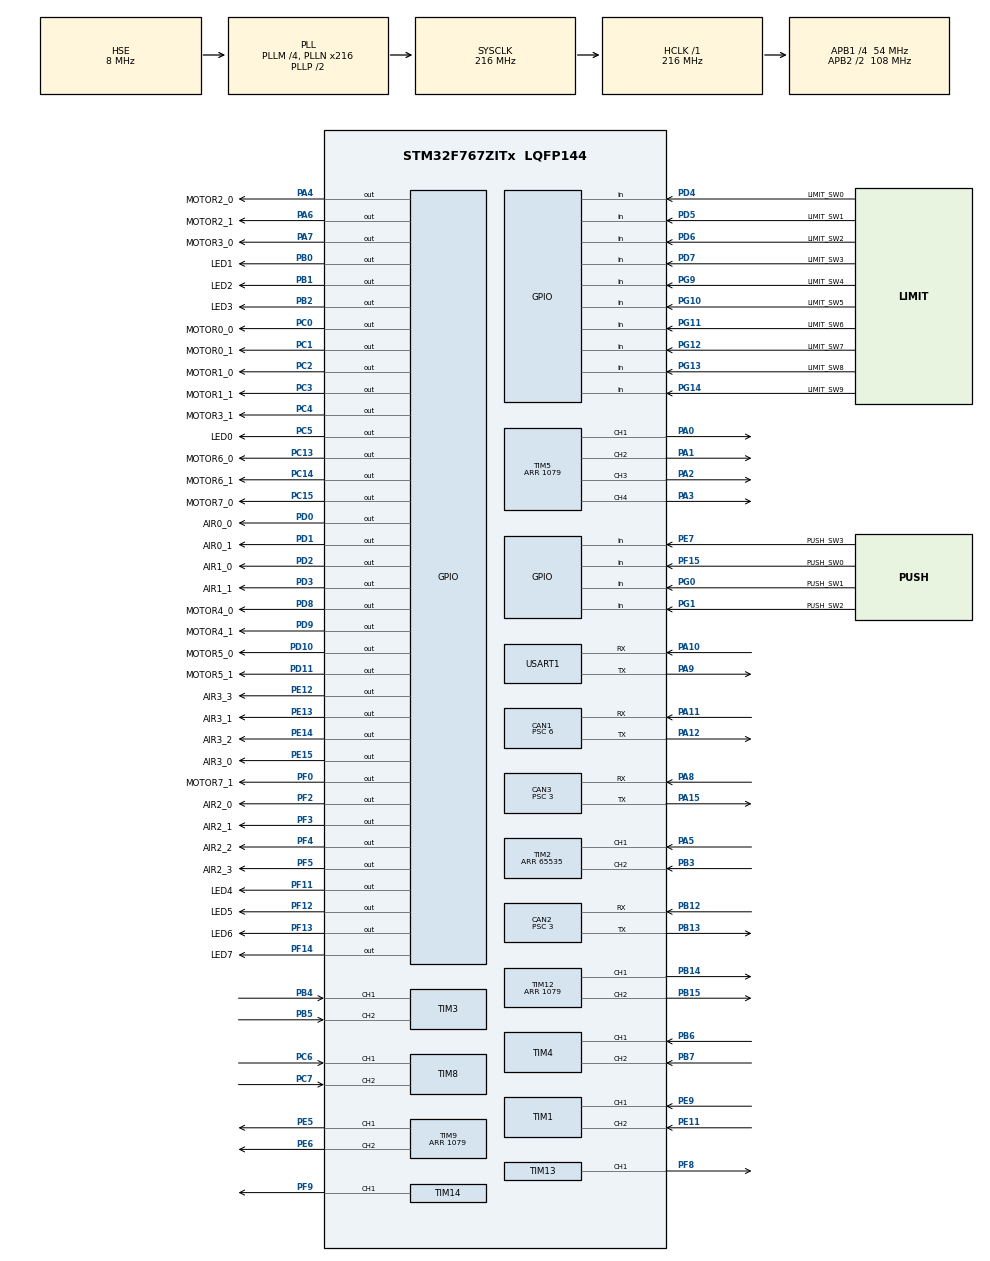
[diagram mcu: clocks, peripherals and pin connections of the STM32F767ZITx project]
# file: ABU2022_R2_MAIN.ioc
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CAN1.BS1=CAN_BS1_14TQ
CAN1.BS2=CAN_BS2_3TQ
CAN1.CalculateBaudRate=500000
CAN1.CalculateTimeBit=1999.99
CAN1.CalculateTimeQuantum=111.11111111111111
CAN1.Prescaler=6
CAN2.BS1=CAN_BS1_14TQ
CAN2.BS2=CAN_BS2_3TQ
CAN2.CalculateBaudRate=1000000
CAN2.CalculateTimeBit=999.99
CAN2.CalculateTimeQuantum=55.55555555555556
CAN2.Prescaler=3
CAN3.BS1=CAN_BS1_14TQ
CAN3.BS2=CAN_BS2_3TQ
CAN3.CalculateBaudRate=1000000
CAN3.CalculateTimeBit=999.99
CAN3.CalculateTimeQuantum=55.55555555555556
CAN3.Prescaler=3
Mcu.Family=STM32F7
Mcu.Name=STM32F767ZITx
Mcu.Package=LQFP144
NVIC.CAN3_RX0_IRQn=true\:0\:0\:false\:false\:true\:true\:true
NVIC.CAN3_RX1_IRQn=true\:0\:0\:false\:false\:true\:true\:true
NVIC.CAN3_SCE_IRQn=true\:0\:0\:false\:false\:true\:true\:true
NVIC.CAN3_TX_IRQn=true\:0\:0\:false\:false\:true\:true\:true
NVIC.PriorityGroup=NVIC_PRIORITYGROUP_4
NVIC.TIM6_DAC_IRQn=true\:0\:0\:false\:false\:true\:true\:true
NVIC.TIM7_IRQn=true\:0\:0\:false\:false\:true\:true\:true
PA0/WKUP.Signal=S_TIM5_CH1
PA1.Signal=S_TIM5_CH2
PA10.Mode=Asynchronous
PA10.Signal=USART1_RX
PA11.Mode=CAN_Activate
PA11.Signal=CAN1_RX
PA12.Mode=CAN_Activate
PA12.Signal=CAN1_TX
PA13.Mode=Serial_Wire
PA13.Signal=SYS_JTMS-SWDIO
PA14.Mode=Serial_Wire
PA14.Signal=SYS_JTCK-SWCLK
PA15.Mode=CAN_Activate
PA15.Signal=CAN3_TX
PA2.Signal=S_TIM5_CH3
PA3.Signal=S_TIM5_CH4
PA4.GPIO_Label=MOTOR2_0
PA4.Signal=GPIO_Output
PA5.Signal=S_TIM2_CH1_ETR
PA6.GPIO_Label=MOTOR2_1
PA6.Signal=GPIO_Output
PA7.GPIO_Label=MOTOR3_0
PA7.Signal=GPIO_Output
PA8.Mode=CAN_Activate
PA8.Signal=CAN3_RX
PA9.Mode=Asynchronous
PA9.Signal=USART1_TX
PB0.GPIO_Label=LED1
PB0.Signal=GPIO_Output
PB1.GPIO_Label=LED2
PB1.Signal=GPIO_Output
PB12.Mode=CAN_Activate
PB12.Signal=CAN2_RX
PB13.Mode=CAN_Activate
PB13.Signal=CAN2_TX
PB14.Signal=S_TIM12_CH1
PB15.Signal=S_TIM12_CH2
PB2.GPIO_Label=LED3
PB2.Signal=GPIO_Output
PB3.Signal=S_TIM2_CH2
PB4.Signal=S_TIM3_CH1
PB5.Signal=S_TIM3_CH2
PB6.Signal=S_TIM4_CH1
PB7.Signal=S_TIM4_CH2
PC0.GPIO_Label=MOTOR0_0
PC0.Signal=GPIO_Output
PC1.GPIO_Label=MOTOR0_1
PC1.Signal=GPIO_Output
PC13.GPIO_Label=MOTOR6_0
PC13.Signal=GPIO_Output
PC14/OSC32_IN.GPIO_Label=MOTOR6_1
PC14/OSC32_IN.Signal=GPIO_Output
PC15/OSC32_OUT.GPIO_Label=MOTOR7_0
PC15/OSC32_OUT.Signal=GPIO_Output
PC2.GPIO_Label=MOTOR1_0
PC2.Signal=GPIO_Output
PC3.GPIO_Label=MOTOR1_1
PC3.Signal=GPIO_Output
PC4.GPIO_Label=MOTOR3_1
PC4.Signal=GPIO_Output
PC5.GPIO_Label=LED0
PC5.Signal=GPIO_Output
PC6.Signal=S_TIM8_CH1
PC7.Signal=S_TIM8_CH2
PD0.GPIO_Label=AIR0_0
PD0.Signal=GPIO_Output
PD1.GPIO_Label=AIR0_1
PD1.Signal=GPIO_Output
PD10.GPIO_Label=MOTOR5_0
PD10.Signal=GPIO_Output
PD11.GPIO_Label=MOTOR5_1
PD11.Signal=GPIO_Output
PD2.GPIO_Label=AIR1_0
PD2.Signal=GPIO_Output
PD3.GPIO_Label=AIR1_1
PD3.Signal=GPIO_Output
PD4.GPIO_Label=LIMIT_SW0
PD4.Signal=GPIO_Input
PD5.GPIO_Label=LIMIT_SW1
PD5.Signal=GPIO_Input
PD6.GPIO_Label=LIMIT_SW2
PD6.Signal=GPIO_Input
PD7.GPIO_Label=LIMIT_SW3
PD7.Signal=GPIO_Input
PD8.GPIO_Label=MOTOR4_0
PD8.Signal=GPIO_Output
PD9.GPIO_Label=MOTOR4_1
PD9.Signal=GPIO_Output
PE11.Signal=S_TIM1_CH2
PE12.GPIO_Label=AIR3_3
PE12.Signal=GPIO_Output
PE13.GPIO_Label=AIR3_1
PE13.Signal=GPIO_Output
PE14.GPIO_Label=AIR3_2
PE14.Signal=GPIO_Output
PE15.GPIO_Label=AIR3_0
PE15.Signal=GPIO_Output
PE5.Signal=S_TIM9_CH1
PE6.Signal=S_TIM9_CH2
PE7.GPIO_Label=PUSH_SW3
PE7.Signal=GPIO_Input
PE9.Signal=S_TIM1_CH1
PF0.GPIO_Label=MOTOR7_1
PF0.Signal=GPIO_Output
PF11.GPIO_Label=LED4
PF11.Signal=GPIO_Output
PF12.GPIO_Label=LED5
PF12.Signal=GPIO_Output
PF13.GPIO_Label=LED6
PF13.Signal=GPIO_Output
PF14.GPIO_Label=LED7
PF14.Signal=GPIO_Output
PF15.GPIO_Label=PUSH_SW0
PF15.Signal=GPIO_Input
PF2.GPIO_Label=AIR2_0
PF2.Signal=GPIO_Output
PF3.GPIO_Label=AIR2_1
PF3.Signal=GPIO_Output
PF4.GPIO_Label=AIR2_2
PF4.Signal=GPIO_Output
PF5.GPIO_Label=AIR2_3
PF5.Signal=GPIO_Output
PF8.Signal=S_TIM13_CH1
PF9.Signal=S_TIM14_CH1
PG0.GPIO_Label=PUSH_SW1
PG0.Signal=GPIO_Input
PG1.GPIO_Label=PUSH_SW2
PG1.Signal=GPIO_Input
PG10.GPIO_Label=LIMIT_SW5
PG10.Signal=GPIO_Input
PG11.GPIO_Label=LIMIT_SW6
PG11.Signal=GPIO_Input
PG12.GPIO_Label=LIMIT_SW7
PG12.Signal=GPIO_Input
PG13.GPIO_Label=LIMIT_SW8
PG13.Signal=GPIO_Input
PG14.GPIO_Label=LIMIT_SW9
PG14.Signal=GPIO_Input
PG9.GPIO_Label=LIMIT_SW4
PG9.Signal=GPIO_Input
PH0/OSC_IN.Mode=HSE-External-Oscillator
PH0/OSC_IN.Signal=RCC_OSC_IN
PH1/OSC_OUT.Mode=HSE-External-Oscillator
PH1/OSC_OUT.Signal=RCC_OSC_OUT
ProjectManager.HeapSize=0x200
ProjectManager.StackSize=0x400
ProjectManager.TargetToolchain=SW4STM32
RCC.AHBFreq_Value=216000000
RCC.APB1CLKDivider=RCC_HCLK_DIV4
RCC.APB1Freq_Value=54000000
RCC.APB1TimFreq_Value=108000000
RCC.APB2CLKDivider=RCC_HCLK_DIV2
RCC.APB2Freq_Value=108000000
RCC.APB2TimFreq_Value=216000000
RCC.CortexFreq_Value=216000000
RCC.HCLKFreq_Value=216000000
RCC.HSE_VALUE=8000000
RCC.HSI_VALUE=16000000
RCC.LSE_VALUE=32768
RCC.PLLM=4
RCC.PLLN=216
RCC.PLLSourceVirtual=RCC_PLLSOURCE_HSE
RCC.SYSCLKFreq_VALUE=216000000
RCC.SYSCLKSource=RCC_SYSCLKSOURCE_PLLCLK
RCC.USBFreq_Value=216000000
RCC.VCOOutputFreq_Value=432000000
SH.S_TIM12_CH1.0=TIM12_CH1,PWM Generation1 CH1
SH.S_TIM12_CH2.0=TIM12_CH2,PWM Generation2 CH2
SH.S_TIM13_CH1.0=TIM13_CH1,PWM Generation1 CH1
SH.S_TIM14_CH1.0=TIM14_CH1,PWM Generation1 CH1
SH.S_TIM1_CH1.0=TIM1_CH1,Encoder_Interface
SH.S_TIM1_CH2.0=TIM1_CH2,Encoder_Interface
SH.S_TIM2_CH1_ETR.0=TIM2_CH1,Encoder_Interface
SH.S_TIM2_CH2.0=TIM2_CH2,Encoder_Interface
SH.S_TIM3_CH1.0=TIM3_CH1,Encoder_Interface
SH.S_TIM3_CH2.0=TIM3_CH2,Encoder_Interface
SH.S_TIM4_CH1.0=TIM4_CH1,Encoder_Interface
SH.S_TIM4_CH2.0=TIM4_CH2,Encoder_Interface
SH.S_TIM5_CH1.0=TIM5_CH1,PWM Generation1 CH1
SH.S_TIM5_CH2.0=TIM5_CH2,PWM Generation2 CH2
SH.S_TIM5_CH3.0=TIM5_CH3,PWM Generation3 CH3
SH.S_TIM5_CH4.0=TIM5_CH4,PWM Generation4 CH4
SH.S_TIM8_CH1.0=TIM8_CH1,Encoder_Interface
SH.S_TIM8_CH2.0=TIM8_CH2,Encoder_Interface
SH.S_TIM9_CH1.0=TIM9_CH1,PWM Generation1 CH1
SH.S_TIM9_CH2.0=TIM9_CH2,PWM Generation2 CH2
TIM12.Channel-PWM\ Generation1\ CH1=TIM_CHANNEL_1
TIM12.Channel-PWM\ Generation2\ CH2=TIM_CHANNEL_2
TIM12.Period=1079
TIM13.Channel=TIM_CHANNEL_1
TIM13.Period=9999
TIM13.Prescaler=150
TIM14.Channel=TIM_CHANNEL_1
TIM14.Period=9999
TIM14.Prescaler=150
TIM2.Period=65535
TIM5.Channel-PWM\ Generation1\ CH1=TIM_CHANNEL_1
TIM5.Channel-PWM\ Generation2\ CH2=TIM_CHANNEL_2
TIM5.Channel-PWM\ Generation3\ CH3=TIM_CHANNEL_3
TIM5.Channel-PWM\ Generation4\ CH4=TIM_CHANNEL_4
TIM5.Period=1079
TIM6.Period=9999
TIM6.Prescaler=269
TIM7.Period=9999
TIM7.Prescaler=539
TIM9.Channel-PWM\ Generation1\ CH1=TIM_CHANNEL_1
TIM9.Channel-PWM\ Generation2\ CH2=TIM_CHANNEL_2
TIM9.Period=1079
USART1.VirtualMode-Asynchronous=VM_ASYNC
VP_TIM13_VS_ClockSourceINT.Mode=Enable_Timer
VP_TIM14_VS_ClockSourceINT.Mode=Enable_Timer
VP_TIM6_VS_ClockSourceINT.Mode=Enable_Timer
VP_TIM7_VS_ClockSourceINT.Mode=Enable_Timer
board=custom

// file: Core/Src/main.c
/* USER CODE BEGIN Header */
/**
  ******************************************************************************
  * @file           : main.c
  * @brief          : Main program body
  ******************************************************************************
  * @attention
  *
  * <h2><center>&copy; Copyright (c) 2022 STMicroelectronics.
  * All rights reserved.</center></h2>
  *
  * This software component is licensed by ST under BSD 3-Clause license,
  * the "License"; You may not use this file except in compliance with the
  * License. You may obtain a copy of the License at:
  *                        opensource.org/licenses/BSD-3-Clause
  *
  ******************************************************************************
  */
/* USER CODE END Header */
#include "main.h"
#include "can.h"
#include "tim.h"
#include "usart.h"
#include "gpio.h"

/* USER CODE BEGIN Includes */
#include "can_com.h"
#include "control.h"
#include "control_main.h"
#include "controller.h"
#include "encoder.h"
#include "motor.h"
#include "servo.h"
/* USER CODE END Includes */

void SystemClock_Config(void);
/* USER CODE BEGIN PFP */
void initialize();
/* USER CODE END PFP */

/* USER CODE BEGIN 0 */
uint8_t pid_stats = 0;
uint8_t disc_number = 0;
uint8_t pile_state = 0;
/* USER CODE END 0 */

int main(void)
{

  /* MCU Configuration--------------------------------------------------------*/

  /* Reset of all peripherals, Initializes the Flash interface and the Systick. */
  HAL_Init();

  /* Configure the system clock */
  SystemClock_Config();

  /* Initialize all configured peripherals */
  MX_GPIO_Init();
  MX_CAN1_Init();
  MX_TIM6_Init();
  MX_USART1_UART_Init();
  MX_TIM1_Init();
  MX_TIM2_Init();
  MX_TIM3_Init();
  MX_TIM5_Init();
  MX_TIM8_Init();
  MX_CAN2_Init();
  MX_TIM4_Init();
  MX_TIM9_Init();
  MX_TIM12_Init();
  MX_CAN3_Init();
  MX_TIM13_Init();
  MX_TIM14_Init();
  MX_TIM7_Init();
  /* USER CODE BEGIN 2 */
  initialize();
  /* USER CODE END 2 */

  /* Infinite loop */
  /* USER CODE BEGIN WHILE */
  while (1)
  {
//	  print("lagori_mode = %d:disc_num = %d\r\n",lagori_mode,get_raspi1().disc);
	  switch (lagori_mode)
	  {
	  case lagori_init:
		  if(GetController().bits.Maru)
		  {
			  LED0_OFF;
			  LED1_OFF;
			  LED2_OFF;
			  LED3_OFF;
			  lagori_mode = lagori_reset;
		  }
		  break;

	  case lagori_reset:
		  while(LIMIT_SW6_OFF)
		  {
			  Motor_6(40);
		  }

		  if(LIMIT_SW6_ON)
		  {
			  Motor_6(0);
		  }

		  while(LIMIT_SW4_OFF)
		  {
			  Motor_5(-15);
		  }

		  if(LIMIT_SW4_ON)
		  {
			  Motor_5(0);
		  }

		  if(LIMIT_SW0_OFF)
		  {
			  Motor_0(-35);
		  }
		  else if(LIMIT_SW0_ON)
		  {
			  LED0_ON;
			  Motor_0(0);
		  }

		  if(LIMIT_SW1_OFF)
		  {
			  Motor_1(-17);
		  }
		  else if(LIMIT_SW1_ON)
		  {
			  LED1_ON;
			  Motor_1(0);
		  }

		  if(LIMIT_SW2_OFF)
		  {
			  Motor_2(-30);
		  }
		  else if(LIMIT_SW2_ON)
		  {
			  LED2_ON;
			  Motor_2(0);
		  }

		  if(LIMIT_SW3_OFF)
		  {
			  Motor_3(-17);
		  }
		  else if(LIMIT_SW3_ON)
		  {
			  LED3_ON;
			  Motor_3(0);
		  }

		  if(LIMIT_SW0_ON && LIMIT_SW1_ON && LIMIT_SW2_ON && LIMIT_SW3_ON)
		  {
			  LED0_ON;
			  LED1_ON;
			  LED2_ON;
			  LED3_ON;
			  Motor_0(0);
			  Motor_1(0);
			  Motor_2(0);
			  Motor_3(0);
			  Motor_6(0);

			  HAL_Delay(200);

			  set_lift_r(0.01);
			  set_lift_l(0);
			  set_arm_right(0);
			  set_arm_left(0);
			  set_partition(0.0);

			  set_target_arm_right(0);
			  set_target_arm_left(0);
			  set_target_lift_right(0);
			  set_target_lift_left(0);
			  set_target_partition(0.0);
			  pid_stats = 1;

			  HAL_Delay(200);

			  lagori_mode = lagori_arm_mode;
		  }
		  break;

	  case lagori_arm_mode:
		  if(GetController().bits.Maru)
		  {
			  set_target_arm_right(get_arm_right_value());
			  set_target_arm_left(get_arm_left_value());
			  pid_stats = 1;
			  if(camera_state == camera_on1)
			  {
				  if(pile_mode == mode1)
				  {
					  disc_number = get_raspi1().disc_camera1;
				  }
				  else if(pile_mode == mode2)
				  {
					  disc_number = get_raspi1().disc_camera2;
				  }

				  if(disc_number >= 1 && disc_number <= 5)
				  {
					  if(get_raspi1().state)
					  {
						  while(arm_ready(0.0) == 0)
						  {
							  LED1_TOGGLE;
						  }
						  lagori_mode = lagori_disc_fix;
					  }
					  else
					  {
						  lagori_mode = lagori_arm_on;
					  }
				  }
			  }
			  else if(camera_state == camera_on2)
			  {
				  if((get_raspi1().disc_camera1 >= 1) && (get_raspi1().disc_camera1 <= 5))
				  {
					  disc_number = get_raspi1().disc_camera1;
				  }
				  else if((get_disc_count() >= 1) && (get_disc_count() <= 5))
				  {
					  disc_number = get_disc_count();
				  }

				  if(disc_number >= 1 && disc_number <= 5)
				  {
					  lagori_mode = lagori_arm_on;
				  }
			  }
		  }
		  else if(GetController().bits.Sankaku)
		  {
			  lagori_mode = lagori_pile;
		  }
		  else if(GetController().bits.Shikaku)
		  {
			  disc_count();
		  }
		  else if(GetController().bits.Batu)
		  {
			  pid_stats = 0;
			  arm_mode_change();
		  }
		  else if(GetController().bits.Start)
		  {
			  camera_state_change();
		  }
		  break;

	  case lagori_disc_fix:
		  switch(disc_number)
		  {
		  case 1:
			  while(lift_right_ready(0.167) == 0)
			  {
				  LED0_TOGGLE;
			  }
			  break;

		  case 2:
			  while(lift_right_ready(0.18) == 0)
			  {
				  LED0_TOGGLE;
			  }

			  break;

		  case 3:
			  while(lift_right_ready(0.26) == 0)
			  {
				  LED0_TOGGLE;
			  }

			  break;

		  case 4:
			  while(lift_right_ready(0.28) == 0)
			  {
				  LED0_TOGGLE;
			  }

			  break;

		  case 5:
			  while(lift_right_ready(0.38) == 0)
			  {
				  LED0_TOGGLE;
			  }

			  break;
		  }

		  while(arm_right_ready(0.4) == 0)
		  {
			  LED1_TOGGLE;
			  Motor_7(50);
		  }

		  if(disc_number == 1)
		  {
			  while(lift_right_ready(0.24) == 0)
			  {
				  LED0_TOGGLE;
			  }
		  }

		  while(arm_right_ready(0.0) == 0)
		  {
			  LED1_TOGGLE;
		  }
		  HAL_Delay(1200);

		  while(lift_right_ready(0.0) == 0)
		  {
			  LED0_TOGGLE;
		  }

		  reset_value();
		  lagori_mode = lagori_arm_mode;

		  break;

	  case lagori_arm_on:
		  switch(disc_number)
		  {
		  case 1:
			  arm_right_ready(0.29);

			  while(arm_left_ready(0.32) == 0)
			  {
				  LED1_TOGGLE;
			  }
			  arm_left_ready(0.35);

			  break;

		  case 2:
			  arm_left_ready(0.12);

			  while(arm_right_ready(0.365) == 0)
			  {
				  LED1_TOGGLE;
			  }
			  arm_right_ready(0.4);

			  break;

		  case 3:
			  arm_left_ready(0.145);

			  while(arm_right_ready(0.270) == 0)
			  {
				  LED1_TOGGLE;
			  }
			  arm_right_ready(0.31);
			  break;

		  case 4:
			  arm_left_ready(0.09);

			  while(arm_right_ready(0.17) == 0)
			  {
				  LED1_TOGGLE;
			  }
			  arm_right_ready(0.24);
			  break;

		  case 5:
			  arm_left_ready(0.1);

			  while(arm_right_ready(0.11) == 0)
			  {
				  LED1_TOGGLE;
			  }
			  arm_right_ready(0.15);

			  break;
		  }

		  HAL_Delay(100);
		  lagori_mode = lagori_lift_up;

		  break;

	  case lagori_lift_up:
		  switch(disc_number)
		  {
		  case 1:
			  lift_up_1();

			  break;

		  case 2:
			  lift_up_2();
			  break;

		  case 3:
			  lift_up_3();
			  break;

		  case 4:
			  if(camera_state == camera_on1)
			  {
				  while(!lift_ready(HIGHT4_CAMERA))
				  {
					  LED0_TOGGLE;
				  }
				  partition_mode = part_on;
				  partition_air = air_down_on;
			  }
			  else
			  {
				  while(!lift_ready(HIGHT4))
				  {
					  LED0_TOGGLE;
				  }
			  }
			  break;

		  case 5:
			  if(camera_state == camera_on1)
			  {
				  while(!lift_ready(HIGHT5))
				  {
					  LED0_TOGGLE;
				  }
				  partition_mode = part_off;
			  }
			  else
			  {
				  while(!lift_ready(HIGHT5))
				  {
					  LED0_TOGGLE;
				  }
			  }
			  break;
		  }

		  if(camera_state == camera_on1)
		  {
			  if(partition_air == air_up_on)
			  {
				  AIR2_0_OFF;
			  }
			  else if(partition_air == air_down_on)
			  {
				  AIR2_1_OFF;
			  }

			  if(partition_mode == part_on)
			  {
				  lagori_mode = partition_on;
			  }
			  else
			  {
				  while(1)
				  {
					  if(GetController().bits.Maru)
					  {
						  lagori_mode = lagori_arm_off;
						  break;
					  }

					  if(disc_number == 1)
					  {
						  if(GetController().bits.Batu)
						  {
							  arm_left_ready(0.44);
							  arm_right_ready(0.22);
						  }
						  else if(GetController().bits.Sankaku)
						  {
							  arm_right_ready(0.44);
							  arm_left_ready(0.22);
						  }
					  }
					  else if(disc_number == 2)
					  {
						  if(GetController().bits.Batu)
						  {
							  arm_left_ready(0.28);
							  arm_right_ready(0.27);
						  }
						  else if(GetController().bits.Sankaku)
						  {
							  arm_right_ready(0.44);
							  arm_left_ready(0.14);
						  }
					  }
				  }
			  }
		  }
		  else
		  {
			  while(1)
			  {
				  if(GetController().bits.Maru)
				  {
					  lagori_mode = lagori_arm_off;
					  break;
				  }

				  if(disc_number == 1)
				  {
					  if(GetController().bits.Batu)
					  {
						  arm_left_ready(0.44);
						  arm_right_ready(0.22);
					  }
					  else if(GetController().bits.Sankaku)
					  {
						  arm_right_ready(0.44);
						  arm_left_ready(0.22);
					  }
				  }
				  else if(disc_number == 2)
				  {
					  if(GetController().bits.Batu)
					  {
						  arm_left_ready(0.28);
						  arm_right_ready(0.27);
					  }
					  else if(GetController().bits.Sankaku)
					  {
						  arm_right_ready(0.44);
						  arm_left_ready(0.14);
					  }
				  }
			  }
		  }
		  break;

	  case partition_on:
		  pile_state = 0;
		  if(disc_number == 4)
		  {
			  while(partition_ready(2.1) == 0)
			  {
				  LED2_TOGGLE;
			  }
		  }
		  else
		  {
			  while(partition_ready(2.0) == 0)
			  {
				  LED2_TOGGLE;
			  }
		  }

		  lagori_mode = lagori_arm_off;
		  break;

	  case lagori_arm_off:
		  while(arm_ready(0.0) == 0)
		  {
			  LED1_TOGGLE;
		  }

		  if(camera_state == camera_on1)
		  {
			  if(disc_number == 5)
			  {
				  lift_ready(0.22);
			  }
			  else if(partition_mode == part_on)
			  {
				  if((disc_number == 2 || disc_number == 3) && (partition_air != air_down_on))
				  {
					  lift_ready(0.0);
				  }
			  }
		  }

		  if(camera_state == camera_on1)
		  {
			  if(partition_mode == part_on)
			  {
				  if(partition_air == air_up_on)
				  {
					  AIR2_0_ON;
					  HAL_Delay(40);
				  }
				  else if(partition_air == air_down_on)
				  {
					  AIR2_1_ON;
					  HAL_Delay(80);
				  }
				  lagori_mode = partition_off;
				  HAL_Delay(20);
			  }
			  else if(disc_number == 5)
			  {
				  while(1)
				  {
					  if(GetController().bits.Batu)
					  {
						  lagori_mode = lagori_lift_down;
						  break;
					  }
					  else if(GetController().bits.Sankaku)
					  {
						  lagori_mode = lagori_pile;
						  break;
					  }
				  }
			  }
			  else
			  {
				  while(1)
				  {
					  if(GetController().bits.Maru)
					  {
						  lagori_mode = lagori_lift_down;
						  break;
					  }
				  }
			  }
		  }
		  else if(camera_state == camera_on2 || camera_state == camera_off)
		  {
			  while(1)
			  {
				  if(GetController().bits.Maru)
				  {
					  lagori_mode = lagori_lift_down;
					  break;
				  }
			  }
		  }
		  break;

	  case partition_off:
		  AIR3_0_OFF;
		  AIR3_1_OFF;
		  AIR3_2_OFF;
		  pile_state = 0;
		  partition_ready(0.23);
		  HAL_Delay(400);

		  if(partition_air == air_down_on)
		  {
			  lift_ready(0.0);
		  }

		  reset_value();
		  partition_air = no_air;
		  partition_mode = part_off;
		  lagori_mode = lagori_arm_mode;
		  break;

	  case lagori_lift_down:
		  while(lift_ready(0.0) == 0)
		  {
			  LED0_TOGGLE;
		  }

		  AIR3_0_OFF;
		  AIR3_1_OFF;
		  AIR3_2_OFF;
		  reset_value();
		  partition_air = no_air;
		  partition_mode = part_off;
		  lagori_mode = lagori_arm_mode;
		  break;

	  case lagori_pile:
		  pile_state = 0;
		  partition_ready(1.95);

		  if(partition_ready(1.95))
		  {
			  AIR2_0_OFF;
			  AIR2_1_OFF;

			  if(LIMIT_SW5_OFF)
			  {
				  Motor_6(-70);
			  }
			  else if(LIMIT_SW5_ON)
			  {
				  Motor_6(0);
				  AIR2_0_OFF;
				  AIR2_1_OFF;
				  HAL_Delay(150);
				  lagori_mode = pile2;
			  }
		  }
		  else if(get_partition_value() > 1.4 && get_partition_value() < 1.7)
		  {
			  if(LIMIT_SW5_OFF)
			  {
				  Motor_6(-70);
			  }
			  else if(LIMIT_SW5_ON)
			  {
				  Motor_6(0);
			  }
		  }
		  break;

	  case pile2:
		  pile_state = 1;
		  while(partition_ready(0.5) == 0)
		  {
			  LED2_TOGGLE;
		  }

		  pile_state = 0;
		  while(partition_ready(0.05) == 0)
		  {
			  LED2_TOGGLE;
		  }

		  while(LIMIT_SW6_OFF)
		  {
			  Motor_6(50);
		  }

		  if(LIMIT_SW6_ON)
		  {
			  Motor_6(0);
		  }

		  while(1)
		  {
			  if(GetController().bits.Maru)
			  {
				  AIR3_0_OFF;
				  AIR3_1_OFF;
				  AIR3_2_OFF;
				  reset_value();
				  partition_air = no_air;
				  partition_mode = part_off;
				  lagori_mode = lagori_lift_down;
				  break;
			  }
		  }
		  break;
	  }

	  if(GetController().bits.Up)
	  {
		  air_mode_change1();
	  }
//	  else if(GetController().bits.Down)
//	  {
//		  air_mode_change2();
//	  }
    /* USER CODE END WHILE */

  }
}

void SystemClock_Config(void)
{
  RCC_OscInitTypeDef RCC_OscInitStruct = {0};
  RCC_ClkInitTypeDef RCC_ClkInitStruct = {0};
  RCC_PeriphCLKInitTypeDef PeriphClkInitStruct = {0};

  /** Configure the main internal regulator output voltage
  */
  __HAL_RCC_PWR_CLK_ENABLE();
  __HAL_PWR_VOLTAGESCALING_CONFIG(PWR_REGULATOR_VOLTAGE_SCALE1);
  /** Initializes the RCC Oscillators according to the specified parameters
  * in the RCC_OscInitTypeDef structure.
  */
  RCC_OscInitStruct.OscillatorType = RCC_OSCILLATORTYPE_HSE;
  RCC_OscInitStruct.HSEState = RCC_HSE_ON;
  RCC_OscInitStruct.PLL.PLLState = RCC_PLL_ON;
  RCC_OscInitStruct.PLL.PLLSource = RCC_PLLSOURCE_HSE;
  RCC_OscInitStruct.PLL.PLLM = 4;
  RCC_OscInitStruct.PLL.PLLN = 216;
  RCC_OscInitStruct.PLL.PLLP = RCC_PLLP_DIV2;
  RCC_OscInitStruct.PLL.PLLQ = 2;
  RCC_OscInitStruct.PLL.PLLR = 2;
  if (HAL_RCC_OscConfig(&RCC_OscInitStruct) != HAL_OK)
  {
    Error_Handler();
  }
  /** Activate the Over-Drive mode
  */
  if (HAL_PWREx_EnableOverDrive() != HAL_OK)
  {
    Error_Handler();
  }
  /** Initializes the CPU, AHB and APB buses clocks
  */
  RCC_ClkInitStruct.ClockType = RCC_CLOCKTYPE_HCLK|RCC_CLOCKTYPE_SYSCLK
                              |RCC_CLOCKTYPE_PCLK1|RCC_CLOCKTYPE_PCLK2;
  RCC_ClkInitStruct.SYSCLKSource = RCC_SYSCLKSOURCE_PLLCLK;
  RCC_ClkInitStruct.AHBCLKDivider = RCC_SYSCLK_DIV1;
  RCC_ClkInitStruct.APB1CLKDivider = RCC_HCLK_DIV4;
  RCC_ClkInitStruct.APB2CLKDivider = RCC_HCLK_DIV2;

  if (HAL_RCC_ClockConfig(&RCC_ClkInitStruct, FLASH_LATENCY_7) != HAL_OK)
  {
    Error_Handler();
  }
  PeriphClkInitStruct.PeriphClockSelection = RCC_PERIPHCLK_USART1;
  PeriphClkInitStruct.Usart1ClockSelection = RCC_USART1CLKSOURCE_PCLK2;
  if (HAL_RCCEx_PeriphCLKConfig(&PeriphClkInitStruct) != HAL_OK)
  {
    Error_Handler();
  }
}

/* USER CODE BEGIN 4 */
void initialize()
{
	InitCan();
	init_encoder();
	motor_on_init();
	init_pid_value();
	AIR2_0_OFF;
	AIR2_1_OFF;

	AIR3_0_OFF;
	AIR3_1_OFF;
	AIR3_2_OFF;
	AIR3_3_OFF;

	lagori_mode = lagori_init;
	arm_mode = mode_on;
	pile_mode = mode1;
	air_mode1 = air_on;
	air_mode2 = air2_off;
	camera_state = camera_on1;
	partition_mode = part_off;
	partition_air = no_air;
	disc_number = 0;
	pid_stats = 0;
	init_raspi1_value();
	reset_loss_count();
	setdata(1);
	setdata_part(0);

	HAL_TIM_Base_Start_IT(&htim6);
	HAL_TIM_Base_Start_IT(&htim7);
}

void HAL_TIM_PeriodElapsedCallback(TIM_HandleTypeDef *htim)
{
	// 25msec
	if (htim == &htim6){
		enc_update();
		UpdateCan_raspi1();

		if(GetController().bits.L_2 || GetController().bits.Select)
		{
			reset_counter();

			if(get_reset_count() > 5)
			{
				All_Motor(0);
				pid_stats = 0;
				HAL_NVIC_SystemReset();
			}
		}
		else
		{
			if(pid_stats)
			{
				control_on_update();
				if(pile_state){
					partition_control_pile();
				}else{
					partition_control();
				}
			}
		}
		slicer();
		disc_led();
	}

	// 50msec
	if(htim == &htim7){
		UpdateController();
		SendData();
	}
}
/* USER CODE END 4 */

void Error_Handler(void)
{
  __disable_irq();
  while (1)
  {
  }
}

/************************ (C) COPYRIGHT STMicroelectronics *****END OF FILE****/
